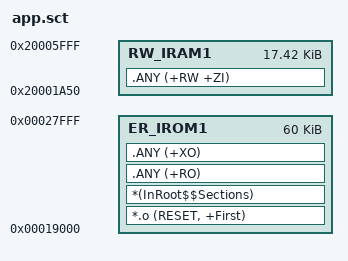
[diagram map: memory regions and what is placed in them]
; *************************************************************
; *** Scatter-Loading Description File generated by uVision ***
; *************************************************************

LR_IROM1 0x00019000 0x0000F000  {    ; load region size_region
  ER_IROM1 0x00019000 0x0000F000  {  ; load address = execution address
   *.o (RESET, +First)
   *(InRoot$$Sections)
   .ANY (+RO)
   .ANY (+XO)
  }
  RW_IRAM1 0x20001A50 0x000045B0  {  ; RW data
   .ANY (+RW +ZI)
  }
}

